# cslr_emif_001 register map
Vendor: Texas Instruments
Peripheral module from a debugger description file.
Registers are 32-bit, read-only, reset 0x0 unless marked. A register's access mark holds for its fields unless they carry their own. Offsets are as the file gives them; lines under a group give offsets from that group; [hi:lo] are bit positions; {n}, {i} and the like mark numbered series; 'fields as' and 'values as' point back to an identical list; <NAME> marks a mode.

## EMIF — External Memory Interface
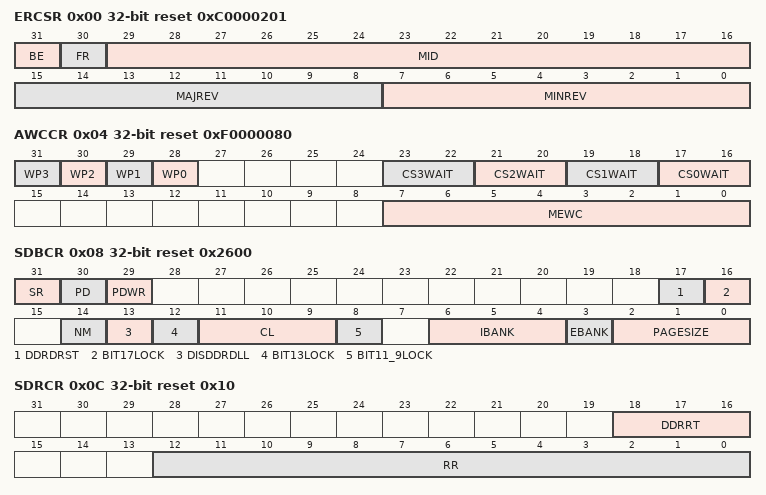
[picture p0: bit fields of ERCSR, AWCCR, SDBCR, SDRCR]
0x00 ERCSR reset 0xC0000201 — EMIF Revision Code and Status register
  [31] BE — Big Endian Status 0: EMIF in little endian mode 1: EMIF in big endian mode
  [30] FR — Full Rate Status 0: EMIF in half rate mode 1: EMIF in full rate mode
  [29:16] MID — EMIF Module ID
  [15:8] MAJREV — EMIF Major Revision Number
  [7:0] MINREV — EMIF Minor Revision Number
0x04 AWCCR access per field reset 0xF0000080 — Asynchronous Wait Cycle Configuration Register
  [n+28] WP{n} rw (n=0..3) — Wait Polarity for pad_wait_i[{n}]. Defines the ploarity of the pad_wait_i[{n}] port, as follows: 0: wait if pad_wait_i[{n}] port is low 1: wait if pad_wait_i[{n}] port is high
    0=WAITLOW (Wait if pad_wait_i[{n}] is low); 1=WAITHIGH (Wait if pad_wait_i[{n}] is high)
  [2n+17:2n+16] CS{n}WAIT rw (n=0..3) — pad_wait_i map bits for chip select {n+2}. 00: pad_wait_i[0] is used 01: pad_wait_i[1] is used 10: pad_wait_i[2] is used 11: pad_wait_i[3] is used
  [7:0] MEWC rw — Maximum External Wait Cycles The EMIF will wait for (MEWC + 1)*16 clock cycles before an extended asynchronous cycle is terminated.
0x08 SDBCR access per field reset 0x2600 (reset mask 0xFFFFFF8F) — SDRAM Bank Configuration Register
  [31] SR rw — Self Refresh Setting this bit to 1 will place the SDRAM in self refresh mode. The EMIF will service all asynchronous bank accesses immediately, but any other SDRAM access will require at least 16 cycles. The 16 cycles are needed to take the SDRAM out of self refresh mode. If an SDRAM access follows setting this bit, the SDRAM access will take at least TRAS + TXSR + 2
  [30] PD rw — Power Down Writing a 1 to this bit will cause connected SDRAM devices to be placed into Power Down mode and the EMIF to enter the power down state
  [29] PDWR rw — Power Down with Refreshes Writing a 1 to this bit will cause the EMIF to exit the power down state and issue an AUTOREFRESH command every time Refresh May level is set
  [17] DDRDRST rw — DDR SDRAM drive strength. Set to 0 for normal drive strength. Set to 1 for weak drive strength. A write to this field will cause the EMIF to start the SDRAM initialization sequence.
  [16] BIT17LOCK rw — Bit 17 can only be written if this bit is set to 1. This bit will always read 0.
  [14] NM rw — Narrow Mode Reflects if the EMIF data bus is set to 16 or 32 bits 0: 32-bit data bus is used 1: 16-bit data bus is used
  [13] DISDDRDLL rw — Disable DLL select for DDR1 SDRAM Set to 1 to disable DLL inside DDR1 SDRAM
  [12] BIT13LOCK rw — Bit 13 can only be written if this bit is set to 1. This bit will always read 0
  [11:9] CL rw — CAS Latency Value of CAS latency to be used when accessing SDRAM. Only CAS latencies of 2 (cl = 2) and 3 (cl = 3) are supported for SDR SDRAM. For DDR1 SDRAM, this field supports all values equal to the CAS latency field values supported in the Mode Register inside the DDR1 SDRAM A write to this field will cause the EMIF to start the SDRAM initialization sequence
    2=CASLAT2 (CAS Latency of 3)
  [8] BIT11_9LOCK rw — Bits 11 to 9 can only be written if this bit is set to 1. This bit will always read 0
  [6:4] IBANK rw — Internal SDRAM Bank Setup Defines the number of banks inside the SDRAM connected to DA300.
    0=SD1BANK (1 bank SDRAM device)
  [3] EBANK rw — External SDRAM Bank Setup Defines whether the SDRAM bank accesses will use 1 or 2 chip select lines. A write to this field will cause the EMIF to start the SDRAM initialization sequence 0: CS0 is used for SDRAM accesses 1: CS0 and CS1 are used for SDRAM accesses
  [2:0] PAGESIZE rw — Page Size Defines the internal page size of the connected SDRAM devices 0: 256-word pages requiring A[7:0] address pins 1: 512-word pages requiring A[8:0] address pins 2: 1024-word pages requiring A[9:0] address pins 3: 2048-word pages requiring A[10:0] address pins
0x0C SDRCR access per field reset 0x10 — SDRAM Refresh Control Register
  [18:16] DDRRT rw — DDR Refresh Threshold Value in this field should be equal to the number of refreshes should be equal to the number of refreshes that can be missed, minus one. The default value is 0x0 indicating that only one refresh can be missed
  [12:0] RR rw — Refresh Rate Defines the rate at which EMIF refreshes the connected SDRAM devices. The refresh rate is the number of clock cycles required to cause a refresh interval of 7.8us or 15.7us for the appropriate SDRAM used If Full Rate = 1 Value = Clock / Refresh Rate If Full Rate = 0 Value = Clock / (2* Refresh Rate)
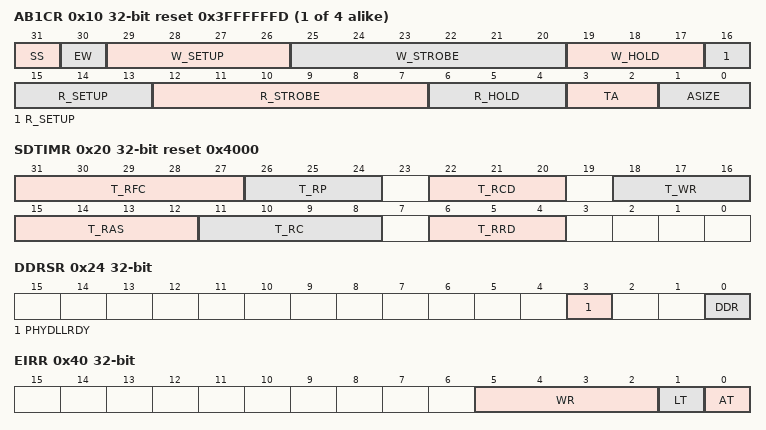
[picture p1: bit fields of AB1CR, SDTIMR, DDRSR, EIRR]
{0xC+4i} AB{i}CR rw reset 0x3FFFFFFD (i=1..4) — Asynchronous Bank {i} Configuration Register
  [31] SS — Select Strobe Set to 1 if chip selects need to have write or read strobe timing
  [30] EW — Extended Wait mode Set to 1 if extended asynchronous cycles are required
  [29:26] W_SETUP — Write Strobe Setup cycles Number of EMIF clock cycles plus one of setup for address (A) and chip enables (CS) before the write strobe (AWE) falls when a write access occurs
  [25:20] W_STROBE — Write Strobe width The width of the write strobe (AWE) in EMIF clock cycles plus one
  [19:17] W_HOLD — Write Strobe Hold width Number of EMIF clock cycles plus one that address (A) is held after write strobe (AWE) rises
  [16:13] R_SETUP — Read Strobe Setup cycles Number of EMIF clock cycles cycles plus one of setup for address (A) and chip enables (CS) before the read strobe (ARE) falls when a read access occurs
  [12:7] R_STROBE — Read Strobe width The width of the read strobe (ARE) in EMIF clock cycles plus one
  [6:4] R_HOLD — Read hold width Number of EMIF clock cycles plus one that address (A) is held after read strobe (ARE) rises
  [3:2] TA — Turn around cycles Number of EMIF clock cycles plus one between the end of one asynchronous bank access and the start of another asynchronous bank access. This delay is not incurred between back-to-back read or back-to-back writes to the same bank
  [1:0] ASIZE — Asynchronous bank data bus size Defines the width of the asynchronous bank's data bus
    0=ASIZE_8BITS (8-bit data bus); 1=ASIZE_16BITS (16-bit data bus)
0x20 SDTIMR access per field reset 0x4000 — SDRAM Timing Register
  [31:27] T_RFC rw — Specifies Trfc value of the SDRAM is minimum number of EMIF clock cycles from Refresh (REFR) or Load Mode (MRS) to Refresh (REFR) or Activate (ACTV) command, minus one TRFC = (Trfc / SDCLK) - 1
  [26:24] T_RP rw — Specifies Trp value of the SDRAM is minimum number of EMIF cycles from Pre-charge to Active (ACTV) or Refresh (REFR/), minus one TRP = (Trp / SDCLK) - 1
  [22:20] T_RCD rw — Specifies Trcd value of the SDRAM is minimum number of EMIF cycles from Active (ACTV) to read (READ) or write (WRITE) command, minus one TRCD = (Trcd / SDCLK) - 1.
  [18:16] T_WR rw — Specifies Twr value of the SDRAM is minimum number of EMIF cycles from last write transfer to Precharge command, minus one TWR = (Twr / SDCLK) - 1
  [15:12] T_RAS rw — Specifies Tras value of the SDRAM in EMIF clock cycles from Activate (ACT) to Precharge command, minus one TRAS = (Tras / SDCLK) - 1
  [11:8] T_RC rw — Specifies Trc value of the SDRAM is minimum number of EMIF clock cycles from Activate (ACT) to Activate (ACT) command, minus one TRC = (Trc / SDCLK) - 1
  [6:4] T_RRD rw — Specifies Trrd value of the SDRAM is minimum number of EMIF clock cycles from Activate (ACT) to Activate (ACT) command for a different bank, minus one TRRD = (Trrd / SDCLK) - 1
0x24 DDRSR — DDR Status Register
  [3] PHYDLLRDY — DDR PHY Ready Reflects the value on the phy_ready port (active high) that defines whether the DDR PHY is ready for normal operation
  [0] DDR — Double Rate Reflects the value on the double_rate port (active high) that defines whether the EMIF is set to operate at double or single data rate
0x28 DDRPHYCR rw — DDR PHY Control Register
  [31:0] DDRPHYCTRL — This register is used to control the DDR PHY. The bit field defintions are DDR PHY specific and should be described in the DDR PHY specification.
0x2C DDRPHYSR — DDR PHY Status Register
  [31:0] DDRPHYSTAT — This register is used to monitor the status of the DDR PHY. The bit field definitions are DDR PHY specific and should be described in the DDR Phy specification.
0x30 TOTAR — Total Accesses Register
  [31:0] TA — The total number of SDRAM accesses This register is used for performance monitoring and is cleared only on reset
0x34 TOTACTR — Total Activate Register
  [31:0] TACT — The total number of SDRAM accesses which require an activate command This register is used for performance monitoring and is cleared only on reset
0x38 DDRPHYID_REV rw — DDR PHY ID and Revision Register
  [31:0] DDRPHYID_REV — This register is specifies the module ID and revision of the DDR PHY begin used The bit field definitions are DDR PHY specific and should be described in the DDR PHY specification
0x3C SDSRETR access per field — SDRAM Self Refresh Exit Timing Register
  [4:0] T_XS rw — This is equal to minimum number of EM_CLK cycles from Self Refresh exit to any command, minus one For SDR SDRAM, this count should satisfy tXSR For DDR1 SDRAM this count should satisfy tXSNR
0x40 EIRR access per field — EMIF Interrupt Raw Register
  [5:2] WR rw — Wait Rise. Set to 1 by hardware to indicate rising edge on the corresponding pad_cs_o[5:2] has been detected. The wpN bits in the Async Wait Cycle Config register has no effect on these bits. Writing a 1 will clear these bits as well as the wr_masked bits in the Interrupt Masked register. Writing a 0 has no effect.
  [1] LT rw — Line Trap Set to 1 by the EMIF to indicate an illegal memory access type or invalid cache line size. This bit is cleared by writing a 1 into this bit field
  [0] AT rw — Asynchronous Timeout Set to 1 by the EMIF to indicate that ARDY was not inactivated during an extended asynchronous bank access cycle within the number of cycles defined by the Max Ext Wait bit field in the Asynchronous Wait Cycle Configuration Register. This bit is cleared by writing a 1 into this bit field
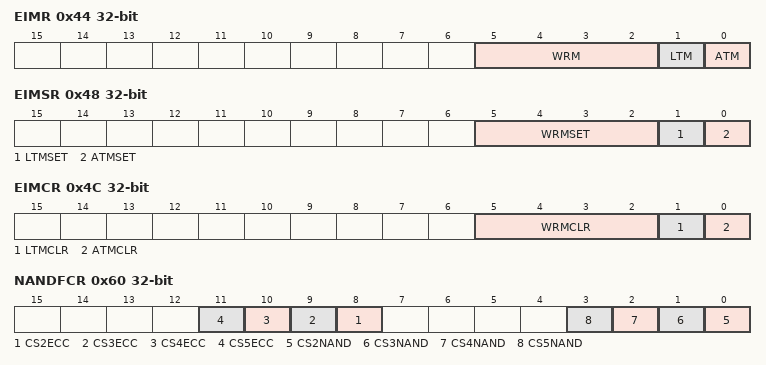
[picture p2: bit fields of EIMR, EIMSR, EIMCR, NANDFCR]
0x44 EIMR access per field — EMIF Interrupt Mask Register
  [5:2] WRM rw — Masked Wait Rise. Set to 1 by hardware to indicate rising edge on the corresponding pad_cs_o[5:2] has been detected. The wpN bits in the Async Wait Cycle Config register has no effect on these bits. Writing a 1 will clear these bits as well as the wr bits in the EMIF Interrupt Raw register. Writing a 0 has no effect.
  [1] LTM rw — Line Trap Mask Bit This bit is cleared by writing a 1 into this bit field
  [0] ATM rw — Asynchronous Timeout Mask Bit This bit is cleared by writing a 1 into this bit field
0x48 EIMSR access per field — EMIF Interrupt Mask Set Register
  [5:2] WRMSET rw — Mask set for wr_masked bits in the Interrupt Masked Register. Writing a 1 will enable the interrupts, and set these bits as well as the WRMCLR bits in the Interrupt Mask Clear register. Writing a 0 has no effect.
  [1] LTMSET rw — Line Trap Mask Set Bit Writing a 1 in this bit field will enable the interrupt and set this bit in the Line Trap Mask bit field of the EMIF Interrupt Mask Clear Register. This bit is cleared by writing a 1 into this bit field
  [0] ATMSET rw — Asynchronous Timeout Mask Set Bit Writing a 1 in this bit field will enable the interrupt and set this bit in the Asynchronous Timeout Mask Clear bit field of the EMIF Interrupt Mask Register. This bit is cleared by writing a 1 into this bit field
0x4C EIMCR access per field — EMIF Interrupt Mask Clear Register
  [5:2] WRMCLR rw — Mask clear for wr_masked bits in the Interrupt Masked Register. Writing a 1 will disable the interrupts, and clear these bits as well as the WRMSET bits in the Interrupt Mask Set register. Writing a 0 has no effect.
  [1] LTMCLR rw — Line Trap Mask Clear Bit Writing a 1 in this bit field will disable the interrupt and clear this bit in the Line Trap Mask Set bit field of the EMIF Interrupt Mask Register. This bit is cleared by writing a 1 into this bit field
  [0] ATMCLR rw — Asynchronous Timeout Mask Clear Bit Writing a 1 in this bit field will disable the interrupt and clear this bit in the Asynchronous Timeout Mask Set bit field of the EMIF Interrupt Mask Register. This bit is cleared by writing a 1 into this bit field
0x50 IOCTRLR access per field — IO Control Register
  [15:0] IOCTRL rw — This register is used to control the IOs such as the VTP calibration of the Ios The bit field definitions are IO specific and should be described in the IO specification
0x54 IOSTATR — IO Status Register
  [3:0] IOSTAT — This register is used to monitor the status of IOs such as the VTP calibration status of the IOs The bit field definitions are IO specific and should be described in the IO specification
0x60 NANDFCR access per field — NAND Flash Control Register
  [n+6] CS{n}ECC rw (n=2..5) — NAND Flash ECC start for chip select {n}. Set to 1 to start ECC calculation on data for NAND Flash on pad_cs_o_n[{n}]
  [n-2] CS{n}NAND rw (n=2..5) — NAND Flash mode for chip select {n}. Set to 1 if using NAND Flash on pad_cs_o_n[{n}]
0x64 NANDFSR — NAND Flash Status Register
  [3:0] WAITST — Raw status of the pad_wait_i[3:0] input. The WPn bits in the AWCCR register has no effect on these bits.
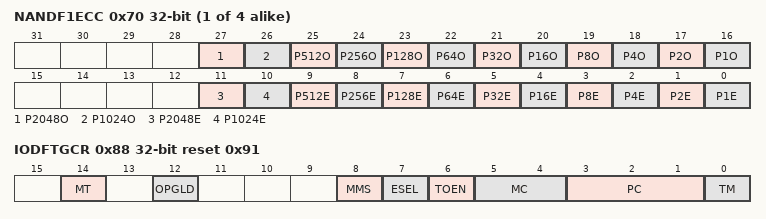
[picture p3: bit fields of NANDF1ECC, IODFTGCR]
{0x6C+4i} NANDF{i}ECC (i=1..4) — NAND Flash {i} ECC Register
  [27] P2048O — ECC code calculated while reading/writing NAND Flash. For 8-bit NAND Flash, p1o, p2o, and p4o are column parities. p8o to p2048o are row parities. For 16-bit NAND Flash, p1o, p2o, p4o and p8o are column parities. p16o to p2048o are row parities.
  [26] P1024O
  [25] P512O
  [24] P256O
  [23] P128O
  [22] P64O
  [21] P32O
  [20] P16O
  [19] P8O
  [18] P4O
  [17] P2O
  [16] P1O
  [11] P2048E — ECC code calculated while reading/writing NAND Flash. For 8-bit NAND Flash, p1o, p2o, and p4o are column parities. p8o to p2048o are row parities. For 16-bit NAND Flash, p1o, p2o, p4o and p8o are column parities. p16o to p2048o are row parities.
  [10] P1024E
  [9] P512E
  [8] P256E
  [7] P128E
  [6] P64E
  [5] P32E
  [4] P16E
  [3] P8E
  [2] P4E
  [1] P2E
  [0] P1E
0x84 IODFTECR access per field — IODFT Test Logic Execution Counter Register
  [15:0] TLEC rw — Contains the number of cycles that the MISR signature will be accumulated. Upon of the counter the MISR capture will be turned off.
0x88 IODFTGCR access per field reset 0x91 — IODFT Test Logic Global Control Register
  [14] MT rw — MISR on/off trigger command. These monitor trigger codes only are effective for the MISR signature capture when mc = 0x3. 0: inactive/no effect 1: MISR capture start on the first active cycle decode of control bus activity and continues to update the signature until the IODFT Test Logic Execution Counter expires.
  [12] OPGLD rw — Load pattern generator's initial value. Set to 1 to load an initial value in the pattern generators from the IODFT Test Logic Execution Counter Register.
  [8] MMS rw — Chooses the source of the MISR input. 0: Output register 1: Input capture
  [7] ESEL rw — Output enable select 0: Test mode, and the functional output enable is gated off 1: Normal functional mode
  [6] TOEN rw — Test output enable control. This signal is paired with ESEL. TOEN is never 1 when ESEL is 1. When ESEL is 0 (test mode), TOEN is: 0: Output enabled 1: Output disabled
  [5:4] MC rw — MISR state. 0: download results 1: hold current value 2: load initial value from PC bits 3: MISR enable to capture signature
  [3:1] PC rw — Pattern code. Defines the type of pattern that is selected for the pattern generators. For output pattern generator: 0: functional 1: random XOR 2: random XNOR 3: 8 bit shifter 4: hold current register value For input pattern generator: 0: functional 4: hold current register value 5: random XOR 6: random XNOR 7: 8 bit shifter
  [0] TM rw — Functional mode enable. 0: IODFT mode 1: Functional mode
0x90 IODFTMRLR — IODFT Test Logic MISR Result LSB Register
  [31:0] TLMR — This contains the least significant of the MISR result signature of a given test after the download function is executed.
0x94 IODFTMRMR — IODFT Test Logic MISR Result MID Register
  [31:0] TLMR — This contains the middle bits of the MISR result signature of a given test after the download function is executed.
0x98 IODFTMRMSBR — IODFT Test Logic MISR Result MID Register
  [31:0] TLMR — This contains the most significant bits of the MISR result signature of a given test after the download function is executed.
0xB0 MODRNR reset 0x3 — Module Release Number Register
  [7:0] RLNUM — Release Number. This number tracks EMIF code releases.
